# GD32L235x register map
File version: 1.0
CPU: CM23 r1p0, little endian, no MPU, no FPU, 2 interrupt priority bits
Registers are 32-bit, read-write, reset 0x0 unless marked. A register's access mark holds for its fields unless they carry their own. Offsets are from the block's base; [hi:lo] are bit positions; {n}, {i} and the like mark numbered series.

## CAU — Cryptographic acceleration unit
Base 0x50060000
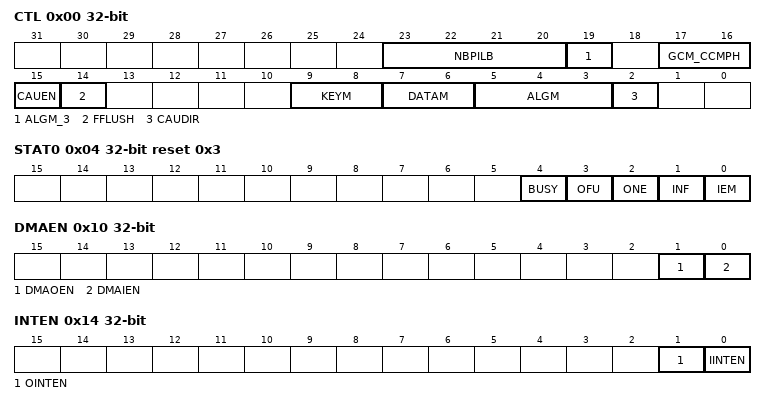
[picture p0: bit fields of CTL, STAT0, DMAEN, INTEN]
0x00 CTL access per field — CAU control register
  [23:20] NBPILB rw — Number of bytes padding in last block of payload
  [19] ALGM_3 rw — Encryption/decryption algorithm mode bit 3
  [17:16] GCM_CCMPH rw — GCM CCM phase
  [15] CAUEN rw — Cryptographic module enable
  [14] FFLUSH wo — FIFO flush
  [9:8] KEYM rw — AES key size mode configuration
  [7:6] DATAM rw — Data swapping type mode configuration
  [5:3] ALGM rw — Encryption/decryption algorithm mode
  [2] CAUDIR rw — CAU direction
0x04 STAT0 ro reset 0x3 — CAU status register 0
  [4] BUSY — BUSY flag
  [3] OFU — OUT FIFO full flag
  [2] ONE — OUT FIFO not empty flag
  [1] INF — IN FIFO not full flag
  [0] IEM — IN FIFO empty flag
0x08 DI — CAU data input register
  [31:0] DI — Data input
0x0C DO ro — CAU data output register
  [31:0] DO — Data output
0x10 DMAEN — CAU DMA enable register
  [1] DMAOEN — Out FIFO DMA enable
  [0] DMAIEN — In FIFO DMA enable
0x14 INTEN — CAU interrupt enable register
  [1] OINTEN — Out FIFO interrupt enable
  [0] IINTEN — In FIFO interrupt enable
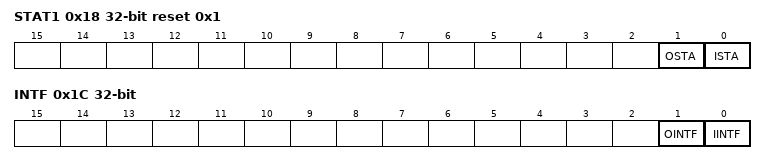
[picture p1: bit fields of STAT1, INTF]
0x18 STAT1 ro reset 0x1 — CAU interrupt status flag register 1
  [1] OSTA — Out FIFO interrupt flag
  [0] ISTA — In FIFO interrupt flag
0x1C INTF ro — CAU enable interrupt status flag register
  [1] OINTF — Out FIFO enabled interrupt flag
  [0] IINTF — In FIFO enabled interrupt flag
{0x20+8i} KEY{i}H wo (i=0..3) — CAU key register
  [31:0] KEY{i}H — Key for DES,TDES,AES
{0x24+8i} KEY{i}L wo (i=0..3) — CAU key register
  [31:0] KEY{i}L — Key for DES,TDES,AES
0x40 IV0H — CAU initialization register
  [31:0] IV0H — The initialization vector for DES,TDES,AES
0x44 IV0L — CAU initialization register
  [31:0] IV0L — The initialization vector for DES,TDES,AES
0x48 IV1H — CAU initialization register
  [31:0] IV1H — The initialization vector for DES,TDES,AES
0x4C IV1L — CAU initialization register
  [31:0] IV1L — The initialization vector for DES,TDES,AES
{0x50+4i} GCMCCMCTXS{i} (i=0..7) — GCM or CCM mode context switch register {i}
  [31:0] CTX{i} — The internal status of the CAU core
{0x70+4i} GCMCTXS{i} (i=0..7) — GCM mode context switch register {i}
  [31:0] CTX{i} — The internal status of the CAU core

## CMP — Comparator
Base 0x40017C00
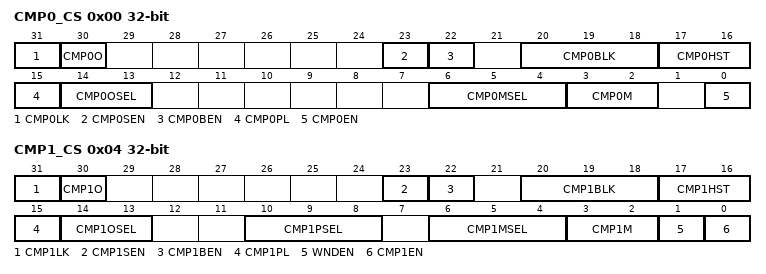
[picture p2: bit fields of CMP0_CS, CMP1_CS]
0x00 CMP0_CS access per field — CMP0 control and status register
  [31] CMP0LK rw — CMP0 lock
  [30] CMP0O ro — CMP0 output state
  [23] CMP0SEN rw — Voltage scaler enable bit
  [22] CMP0BEN rw — Scaler bridge enable bit
  [20:18] CMP0BLK rw — CMP0 output blanking source
  [17:16] CMP0HST rw — CMP0 hysteresis
  [15] CMP0PL rw — Polarity of CMP0 output
  [14:13] CMP0OSEL rw — CMP0 output selection
  [6:4] CMP0MSEL rw — CMP0_IM input selection
  [3:2] CMP0M rw — CMP0 mode
  [0] CMP0EN rw — CMP0 enable
0x04 CMP1_CS access per field — CMP1 control and status register
  [31] CMP1LK rw — CMP1 lock
  [30] CMP1O ro — CMP1 output state
  [23] CMP1SEN rw — Voltage scaler enable bit
  [22] CMP1BEN rw — Scaler bridge enable bit
  [20:18] CMP1BLK rw — CMP1 output blanking source
  [17:16] CMP1HST rw — CMP1 hysteresis
  [15] CMP1PL rw — Polarity of CMP1 output
  [14:13] CMP1OSEL rw — CMP1 output selection
  [10:8] CMP1PSEL rw — CMP1_IP input selection
  [6:4] CMP1MSEL rw — CMP1_IM input selection
  [3:2] CMP1M rw — CMP1 mode
  [1] WNDEN rw — Windows mode enable
  [0] CMP1EN rw — CMP1 enable

## CRC — cyclic redundancy check calculation unit
Base 0x40023000
0x00 DATA reset 0xFFFFFFFF
  [31:0] DATA — CRC calculation result bits
0x04 FDATA — Free data register
  [7:0] FDATA — General-purpose 8-bit data register bits
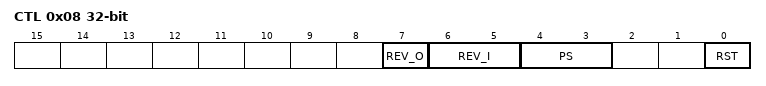
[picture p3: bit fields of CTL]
0x08 CTL — Control register
  [7] REV_O — Reverse output data value in bit order
  [6:5] REV_I — Reverse type for input data
  [4:3] PS — Size of polynomial
  [0] RST — reset bit
0x10 IDATA reset 0xFFFFFFFF — Initialization data register
  [31:0] IDATA — Configurable initial CRC data value
0x14 POLY reset 0x4C11DB7 — Polynomial register
  [31:0] POLY — User configurable polynomial value
